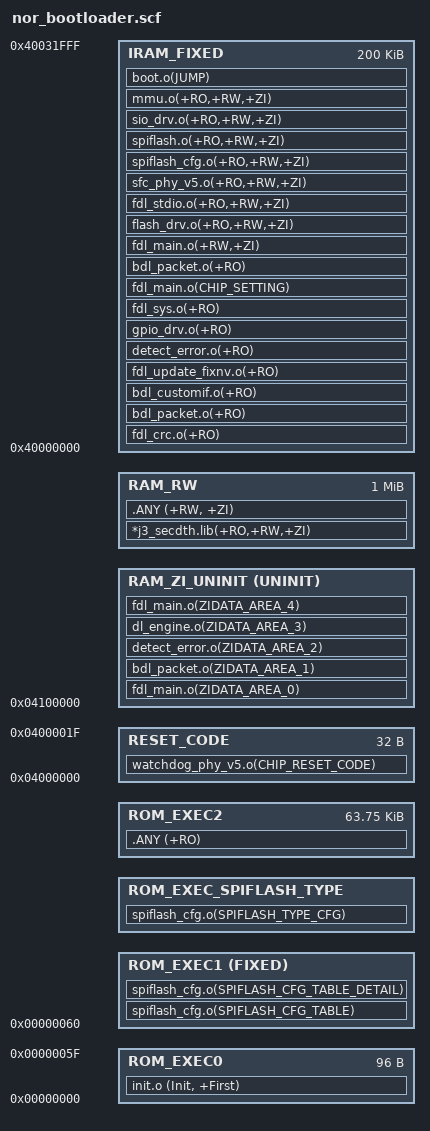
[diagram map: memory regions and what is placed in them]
ROM_LOAD 0x00000000 0x10000
{
	ROM_EXEC0 0x00000000 0x60
	{
		init.o (Init, +First)
	}    
	
	ROM_EXEC1 0x60 FIXED
	{
		spiflash_cfg.o(SPIFLASH_CFG_TABLE)
		spiflash_cfg.o(SPIFLASH_CFG_TABLE_DETAIL)
	}
	
	ROM_EXEC_SPIFLASH_TYPE +0x0
	{
		spiflash_cfg.o(SPIFLASH_TYPE_CFG)
	}
	
	ROM_EXEC2 +0x0 0xFF00
	{
		.ANY (+RO)
	}
	
	RESET_CODE 0x04000000 0x20
	{
		watchdog_phy_v5.o(CHIP_RESET_CODE)      
	}
	
	RAM_ZI_UNINIT 0x04100000  UNINIT 
	{
		fdl_main.o(ZIDATA_AREA_0)
		bdl_packet.o(ZIDATA_AREA_1)
		detect_error.o(ZIDATA_AREA_2)
		dl_engine.o(ZIDATA_AREA_3)
		fdl_main.o(ZIDATA_AREA_4) 	        
	}
	RAM_RW +0 0x100000
	{            
		*j3_secdth.lib(+RO,+RW,+ZI)
		.ANY (+RW, +ZI)
	
	}
	
	IRAM_FIXED 0x40000000 0x32000
	{  
		fdl_crc.o(+RO)
		bdl_packet.o(+RO)
		bdl_customif.o(+RO)
		fdl_update_fixnv.o(+RO)
		detect_error.o(+RO)
		gpio_drv.o(+RO)
		fdl_sys.o(+RO)
		fdl_main.o(CHIP_SETTING)
		bdl_packet.o(+RO)
		fdl_main.o(+RW,+ZI)
		flash_drv.o(+RO,+RW,+ZI)
		fdl_stdio.o(+RO,+RW,+ZI)
		sfc_phy_v5.o(+RO,+RW,+ZI)
		spiflash_cfg.o(+RO,+RW,+ZI)
		spiflash.o(+RO,+RW,+ZI)	   
		sio_drv.o(+RO,+RW,+ZI)
		mmu.o(+RO,+RW,+ZI)
		boot.o(JUMP)    
	}   
}

